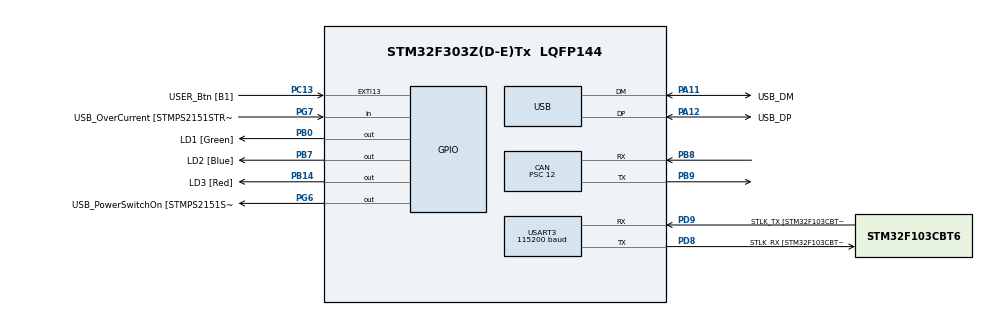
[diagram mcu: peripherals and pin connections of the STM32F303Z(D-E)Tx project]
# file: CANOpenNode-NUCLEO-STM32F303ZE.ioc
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CAN.BS1=CAN_BS1_10TQ
CAN.CalculateBaudRate=249999
CAN.CalculateTimeBit=4000
CAN.CalculateTimeQuantum=333.33333333333337
CAN.NART=ENABLE
CAN.Prescaler=12
Mcu.Family=STM32F3
Mcu.Name=STM32F303Z(D-E)Tx
Mcu.Package=LQFP144
NVIC.CAN_RX1_IRQn=true\:0\:0\:false\:false\:true\:true\:true\:true
NVIC.CAN_SCE_IRQn=true\:0\:0\:false\:false\:true\:true\:true\:true
NVIC.PriorityGroup=NVIC_PRIORITYGROUP_4
NVIC.TIM1_TRG_COM_TIM17_IRQn=true\:0\:0\:false\:false\:true\:true\:true\:true
NVIC.USB_HP_CAN_TX_IRQn=true\:0\:0\:false\:false\:true\:true\:true\:true
NVIC.USB_LP_CAN_RX0_IRQn=true\:0\:0\:false\:false\:true\:true\:true\:true
PA11.GPIO_Label=USB_DM
PA11.Mode=Device
PA11.Signal=USB_DM
PA12.GPIO_Label=USB_DP
PA12.Mode=Device
PA12.Signal=USB_DP
PA13.GPIO_Label=TMS
PA13.Mode=Serial_Wire
PA13.Signal=SYS_JTMS-SWDIO
PA14.GPIO_Label=TCK
PA14.Mode=Serial_Wire
PA14.Signal=SYS_JTCK-SWCLK
PB0.GPIO_Label=LD1 [Green]
PB0.Signal=GPIO_Output
PB14.GPIO_Label=LD3 [Red]
PB14.Signal=GPIO_Output
PB3.GPIO_Label=SWO
PB3.Signal=SYS_JTDO-TRACESWO
PB7.GPIO_Label=LD2 [Blue]
PB7.Signal=GPIO_Output
PB8.Mode=CAN_Activate
PB8.Signal=CAN_RX
PB9.Mode=CAN_Activate
PB9.Signal=CAN_TX
PC13.GPIO_Label=USER_Btn [B1]
PC13.Signal=GPXTI13
PC14-OSC32_IN.Mode=LSE-External-Oscillator
PC14-OSC32_IN.Signal=RCC_OSC32_IN
PC15-OSC32_OUT.Mode=LSE-External-Oscillator
PC15-OSC32_OUT.Signal=RCC_OSC32_OUT
PD8.GPIO_Label=STLK_RX [STM32F103CBT6_PA3]
PD8.Mode=Asynchronous
PD8.Signal=USART3_TX
PD9.GPIO_Label=STLK_TX [STM32F103CBT6_PA2]
PD9.Mode=Asynchronous
PD9.Signal=USART3_RX
PF0-OSC_IN.GPIO_Label=MCO [STM32F103CBT6_PA8]
PF0-OSC_IN.Mode=HSE-External-Clock-Source
PF0-OSC_IN.Signal=RCC_OSC_IN
PG6.GPIO_Label=USB_PowerSwitchOn [STMPS2151STR_EN]
PG6.Signal=GPIO_Output
PG7.GPIO_Label=USB_OverCurrent [STMPS2151STR_FAULT]
PG7.Signal=GPIO_Input
ProjectManager.HeapSize=0x200
ProjectManager.StackSize=0x400
ProjectManager.TargetToolchain=STM32CubeIDE
RCC.AHBFreq_Value=72000000
RCC.APB1CLKDivider=RCC_HCLK_DIV2
RCC.APB1Freq_Value=36000000
RCC.APB1TimFreq_Value=72000000
RCC.APB2Freq_Value=72000000
RCC.APB2TimFreq_Value=72000000
RCC.CortexFreq_Value=72000000
RCC.HCLKFreq_Value=72000000
RCC.HSE_VALUE=8000000
RCC.HSI_VALUE=8000000
RCC.PLLMUL=RCC_PLL_MUL9
RCC.PRESCALERUSB=RCC_USBCLKSOURCE_PLL_DIV1_5
RCC.SYSCLKFreq_VALUE=72000000
RCC.SYSCLKSourceVirtual=RCC_SYSCLKSOURCE_PLLCLK
RCC.USBFreq_Value=48000000
TIM17.Period=999
TIM17.Prescaler=71
USART3.BaudRate=115200
USART3.VirtualMode-Asynchronous=VM_ASYNC
VP_RTC_VS_RTC_Activate.Mode=RTC_Enabled
VP_TIM17_VS_ClockSourceINT.Mode=Enable_Timer
board=NUCLEO-F303ZE

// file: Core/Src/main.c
/* USER CODE BEGIN Header */
/**
  ******************************************************************************
  * @file           : main.c
  * @brief          : Main program body
  ******************************************************************************
  * @attention
  *
  * Copyright (c) 2022 STMicroelectronics.
  * All rights reserved.
  *
  * This software is licensed under terms that can be found in the LICENSE file
  * in the root directory of this software component.
  * If no LICENSE file comes with this software, it is provided AS-IS.
  *
  ******************************************************************************
  */
/* USER CODE END Header */
#include "main.h"
#include "can.h"
#include "rtc.h"
#include "tim.h"
#include "usart.h"
#include "gpio.h"

void SystemClock_Config(void);
/* USER CODE BEGIN PFP */
int mainCAN (void);
/* USER CODE END PFP */

/* USER CODE BEGIN 0 */
int __io_putchar(int ch) {
	while ((USART3->ISR & USART_ISR_TXE) == 0x00); // Wait until TXE is zero
	USART3->TDR = ch;
}
/* USER CODE END 0 */

int main(void)
{

  /* MCU Configuration--------------------------------------------------------*/

  /* Reset of all peripherals, Initializes the Flash interface and the Systick. */
  HAL_Init();

  /* Configure the system clock */
  SystemClock_Config();

  /* Initialize all configured peripherals */
  MX_GPIO_Init();
  MX_RTC_Init();
  MX_USART3_UART_Init();
  MX_USB_PCD_Init();
  MX_CAN_Init();
  MX_TIM17_Init();
  /* USER CODE BEGIN 2 */
  main_canopen();
  /* USER CODE END 2 */

  /* Infinite loop */
  while (1)
  {

  }
}

void SystemClock_Config(void)
{
  LL_FLASH_SetLatency(LL_FLASH_LATENCY_1);
  while(LL_FLASH_GetLatency()!= LL_FLASH_LATENCY_1)
  {
  }
  LL_RCC_HSE_EnableBypass();
  LL_RCC_HSE_Enable();

   /* Wait till HSE is ready */
  while(LL_RCC_HSE_IsReady() != 1)
  {

  }
  LL_RCC_LSI_Enable();

   /* Wait till LSI is ready */
  while(LL_RCC_LSI_IsReady() != 1)
  {

  }
  LL_PWR_EnableBkUpAccess();
  if(LL_RCC_GetRTCClockSource() != LL_RCC_RTC_CLKSOURCE_LSI)
  {
    LL_RCC_ForceBackupDomainReset();
    LL_RCC_ReleaseBackupDomainReset();
    LL_RCC_SetRTCClockSource(LL_RCC_RTC_CLKSOURCE_LSI);
  }
  LL_RCC_EnableRTC();
  LL_RCC_PLL_ConfigDomain_SYS(LL_RCC_PLLSOURCE_HSE, LL_RCC_PLL_MUL_6, LL_RCC_PREDIV_DIV_1);
  LL_RCC_PLL_Enable();

   /* Wait till PLL is ready */
  while(LL_RCC_PLL_IsReady() != 1)
  {

  }
  LL_RCC_SetAHBPrescaler(LL_RCC_SYSCLK_DIV_1);
  LL_RCC_SetAPB1Prescaler(LL_RCC_APB1_DIV_2);
  LL_RCC_SetAPB2Prescaler(LL_RCC_APB2_DIV_1);
  LL_RCC_SetSysClkSource(LL_RCC_SYS_CLKSOURCE_PLL);

   /* Wait till System clock is ready */
  while(LL_RCC_GetSysClkSource() != LL_RCC_SYS_CLKSOURCE_STATUS_PLL)
  {

  }
  LL_SetSystemCoreClock(48000000);

   /* Update the time base */
  if (HAL_InitTick (TICK_INT_PRIORITY) != HAL_OK)
  {
    Error_Handler();
  }
  LL_RCC_SetUSARTClockSource(LL_RCC_USART3_CLKSOURCE_PCLK1);
  LL_RCC_SetTIMClockSource(LL_RCC_TIM17_CLKSOURCE_PCLK2);
  LL_RCC_SetUSBClockSource(LL_RCC_USB_CLKSOURCE_PLL);
}

void Error_Handler(void)
{
  __disable_irq();
  while (1)
  {
  }
}
